# CEC1702 register map
Vendor: Microchip
Registers are 32-bit, read-write, reset 0x0 unless marked. A register's access mark holds for its fields unless they carry their own. Addresses are absolute, and some are shared; only a register's first bit layout is shown; [hi:lo] are bit positions; {n}, {i} and the like mark numbered series.

## ADC
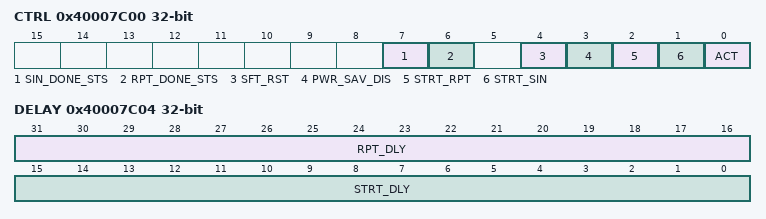
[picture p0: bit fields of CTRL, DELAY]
0x40007C00 CTRL
  [7] SIN_DONE_STS — 0: ADC single-sample conversion is not complete. 1: ADC single-sample conversion is completed. (R/WC)
  [6] RPT_DONE_STS — 0: ADC repeat-sample conversion is not complete. 1: ADC repeat-sample conversion is completed. (R/WC)
  [4] SFT_RST — (SFT_RST) 1: writing one causes a reset of the ADC block hardware (not the registers) 0: writing zero takes the ADC block out of reset
  [3] PWR_SAV_DIS — 0: Power saving feature is enabled. 1: Power saving feature is disabled.
  [2] STRT_RPT — 0: The ADC Repeat Mode is disabled. 1: The ADC Repeat Mode is enabled.
  [1] STRT_SIN — (STRT_SIN) 0: The ADC Single Mode is disabled. 1: The ADC Single Mode is enabled. Note: This bit is self-clearing
  [0] ACT — 0: The ADC is disabled and placed in its lowest power state. 1: ADC block is enabled for operation.
0x40007C04 DELAY
  [31:16] RPT_DLY — This field determines the interval between conversion cycles when Start_Repeat is 1.
  [15:0] STRT_DLY — This field determines the starting delay before a conversion cycle is begun when Start_Repeat is written with a 1.
0x40007C08 CHAN_STS
  [15:0] STS — All bits are cleared by being written with a '1'. 1=conversion of the corresponding ADC channel is complete; 0=conversion of the corresponding ADC channel is not complete. For enabled single cycles, the SINGLE_DONE_STATUS bit in the. ADC Control Register is also set after all enabled channel conversion are done; for enabled repeat cycles, the REPEAT_DONE_STATUS in the ADC Control Register is also set after all enabled channel conversion are done.
0x40007C0C SNG_EN
  [15:0] S_EN — Each bit in this field enables the corresponding ADC channel when a single cycle of conversions is started when the. START_SINGLE bit in the ADC Control Register is written with a 1. 1=single cycle conversions for this channel are enabled. 0=single cycle conversions for this channel are disabled. Note: If this register is changed while a conversion.
0x40007C10 REPT_EN
  [15:0] R_EN — Each bit in this field enables the corresponding ADC channel for each pass of the Repeated ADC Conversion that is controlled by bit START_REPEAT in the ADC Control Register. 1=repeat conversions for this channel are enabled; 0=repeat conversions for this channel are disabled
{0x40007C14+4i} CHAN_RD{i} (i=0..15)

## TFDP
0x40008C00 MSDATA 8-bit
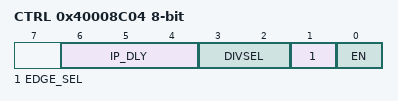
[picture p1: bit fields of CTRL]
0x40008C04 CTRL 8-bit
  [6:4] IP_DLY — Inter-packet Delay. The delay is in terms of TFDP Debug output clocks.
  [3:2] DIVSEL — Clock Divider Select.
  [1] EDGE_SEL — 1= Data is shifted out on the falling edge of the debug clock, 0= Data is shifted out on the rising edge of the debug clock (Default)
  [0] EN — Enable. 1=Clock enabled, 0=Clock is disabled (Default)

## GP_SPI0
0x40009400 ENABLE reset 0xF
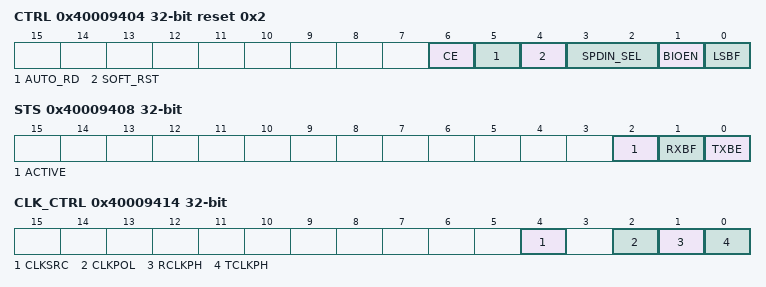
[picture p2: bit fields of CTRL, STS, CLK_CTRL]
0x40009404 CTRL reset 0x2
  [6] CE — SPI Chip Select Enable. 1= SPI_CS# output signal is asserted, i.e., driven to logic '0' 0= SPI_CS# output signal is deasserted, i.e., driven to logic '1'
  [5] AUTO_RD — Auto Read Enable. 1=A read of the SPI RX_DATA Register will clear both the RXBF status bit and the TXBE status bit. 0=A read of the SPI RX_DATA Register will clear the RXBF status bit. The TXBE status bit will not be modified
  [4] SOFT_RST — Soft Reset is a self-clearing bit. Writing zero to this bit has no effect. Writing a one to this bit resets the entire SPI Interface, including all counters and registers back to their initial state.
  [3:2] SPDIN_SEL — [3:2] 1xb=SPDIN1 and SPDIN2. Select this option for Dual Mode [3:2] 01b=SPDIN2 only. Select this option for Half Duplex [3:2] 00b=SPDIN1 only. Select this option for Full Duplex
  [1] BIOEN — Bidirectional Output Enable control. 1=The SPDOUT_Direction signal configures the SPDOUT signal as an output. 0=The SPDOUT_Direction signal configures the SPDOUT signal as an input.
  [0] LSBF — Least Significant Bit First. 1= The data is transferred in LSB-first order. 0= The data is transferred in MSB-first order. (default)
0x40009408 STS ro
  [2] ACTIVE — ACTIVE status
  [1] RXBF — 1=RX_Data buffer is full, 0=RX_Data buffer is not full
  [0] TXBE — 1=TX_Data buffer is empty, 0=TX_Data buffer is not empty
0x4000940C TX_DAT
0x40009410 RX_DAT
0x40009414 CLK_CTRL
  [4] CLKSRC — 1=2MHz, 0=48 MHz Ring Oscillator
  [2] CLKPOL — 1=The SPI_CLK signal is high when the interface is idle and the first clock edge is a falling edge. 0=The SPI_CLK is low when the interface is idle and the first clock edge is a rising edge
  [1] RCLKPH — 1=Valid data on SPDIN signal is expected after the first SPI_CLK edge. This data is sampled on the second and following even SPI_CLK edges (i.e., sample data on falling edge) 0=Valid data is expected on the SPDIN signal on the first SPI_CLK edge. This data is sampled on the first and following odd SPI_-CLK edges (i.e., sample data on rising edge)
  [0] TCLKPH — 1=Valid data is clocked out on the first SPI_CLK edge on SPDOUT signal. The slave device should sample this data on the second and following even SPI_CLK edges (i.e., sample data on falling edge) 0=Valid data is clocked out on the SPDOUT signal prior to the first SPI_CLK edge. The slave device should sample this data on the first and following odd SPI_CLK edges (i.e., sample data on rising edge)
0x40009418 CLK_GEN reset 0x2
  [5:0] PRLD — SPI Clock Generator Preload Value
